# MIMXRT685S_cm33 register map
Vendor: nxp.com; File version: 1.0
CPU: CM33 r2p0, little endian, MPU, FPU, VTOR, 3 interrupt priority bits
Registers are 32-bit, read-write, reset 0x0 unless marked. A register's access mark holds for its fields unless they carry their own. Offsets are from the block's base; [hi:lo] are bit positions; 'fields as' and 'values as' point back to an identical list.

## OSTIMER0 — LPC_Next0 Synchronous OS/Event timer with Wakeup Timer
Base 0x40113000
0x00 EVTIMERL ro — EVTIMER Low Register
  [31:0] EVTIMER_COUNT_VALUE — A read reflects the current value of the lower 32 bits of the EVTIMER. Note there is physically only one EVTimer, readable from all domains.
0x04 EVTIMERH ro — EVTIMER High Register
  [31:0] EVTIMER_COUNT_VALUE — A read reflects the current value of the upper 32 bits of the EVTIMER. Note there is physically only one EVTimer, readable from all domains.
0x08 CAPTURE_L ro — Local Capture Low Register
  [31:0] CAPTURE_VALUE — A read reflects the value of the lower 32 bits of the central EVTIMER at the time the last capture signal was generated by the CPU. A separate pair of CAPTURE registers are implemented for each CPU. Each CPU reads its own capture value at the same pair of addresses.
0x0C CAPTURE_H ro — Local Capture High Register
  [31:0] CAPTURE_VALUE — A read reflects the value of the upper 32 bits of the central EVTIMER at the time the last capture signal was generated by the CPU. A separate pair of CAPTURE registers are implemented for each CPU. Each CPU reads its own capture value at the same pair of addresses.
0x10 MATCH_L — Local Match Low Register
  [31:0] MATCH_VALUE — The value written to the MATCH (L/H) register pair is compared against the central EVTIMER. When a match occurs, an interrupt request is generated if enabled. A separate pair of MATCH registers are implemented for each CPU. Each CPU reads its own local value at the same pair of addresses.
0x14 MATCH_H — Match High Register
  fields as MATCH_L
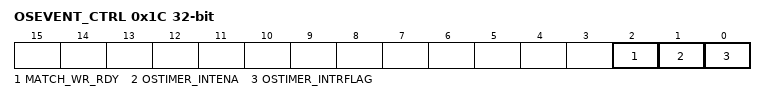
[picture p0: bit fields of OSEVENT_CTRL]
0x1C OSEVENT_CTRL (reset mask 0x3) — OS_EVENT TIMER Control Register
  [2] MATCH_WR_RDY — This bit will be low when it is safe to write to reload the Match Registers. In typical applications it should not be necessary to test this bit.
  [1] OSTIMER_INTENA — When this bit is '1' an interrupt/wakeup request to the Domainn processor will be asserted when the OSTIMER_INTR flag is set. When this bit is '0', interrupt/wakeup requests due to the OSTIMER_INTR flag are blocked.A separate OSEVENT_CTRL register is implemented for each CPU. Each CPU reads its own local value at the same address.
  [0] OSTIMER_INTRFLAG — This bit is set when a match occurs between the central 64-bit EVTIMER and the value programmed in the Match-register pair for the associated CPU This bit is cleared by writing a '1'. Writes to clear this bit are asynchronous. This should be done before a new match value is written into the MATCH_L/H registers

## CRC_ENGINE — LPC_Next0 CRC engine
Base 0x40120000
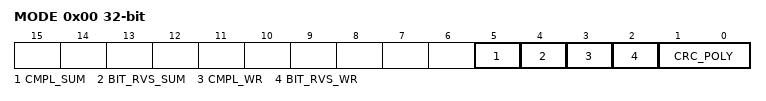
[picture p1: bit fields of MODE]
0x00 MODE — CRC mode register
  [5] CMPL_SUM — CRC sum complement: 1 = 1's complement for CRC_SUM 0 = No 1's complement for CRC_SUM
  [4] BIT_RVS_SUM — CRC sum bit order: 1 = Bit order reverse for CRC_SUM 0 = No bit order reverse for CRC_SUM
  [3] CMPL_WR — Data complement: 1 = 1's complement for CRC_WR_DATA 0 = No 1's complement for CRC_WR_DATA
  [2] BIT_RVS_WR — Data bit order: 1 = Bit order reverse for CRC_WR_DATA (per byte) 0 = No bit order reverse for CRC_WR_DATA (per byte)
  [1:0] CRC_POLY — CRC polynomial: 1X = CRC-32 polynomial 01 = CRC-16 polynomial 00 = CRC-CCITT polynomial
0x04 SEED reset 0xFFFF — CRC seed register
  [31:0] CRC_SEED — A write access to this register will load CRC seed value to CRC_SUM register with selected bit order and 1's complement pre-processes. A write access to this register will overrule the CRC calculation in progresses.
0x08 SUM ro reset 0xFFFF (SUM_WR_DATA view) — CRC checksum register
  [31:0] CRC_SUM — The most recent CRC sum can be read through this register with selected bit order and 1's complement post-processes.
0x08 WR_DATA wo reset not defined (SUM_WR_DATA view) — CRC data register
  [31:0] CRC_WR_DATA — Data written to this register will be taken to perform CRC calculation with selected bit order and 1's complement pre-process. Any write size 8, 16 or 32-bit are allowed and accept back-to-back transactions.
